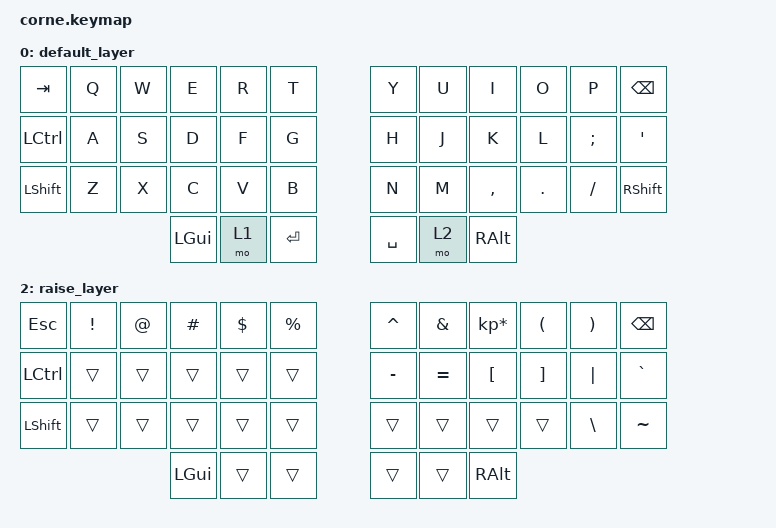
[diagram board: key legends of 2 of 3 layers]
/*
 * Copyright (c) 2020 The ZMK Contributors
 *
 * SPDX-License-Identifier: MIT
 */

#include <behaviors.dtsi>
#include <dt-bindings/zmk/keys.h>
#include <dt-bindings/zmk/bt.h>

/ {
        keymap {
                compatible = "zmk,keymap";

                default_layer {
// -----------------------------------------------------------------------------------------
// |  TAB |  Q  |  W  |  E  |  R  |  T  |   |  Y  |  U   |  I  |  O  |  P  | BKSP |
// | CTRL |  A  |  S  |  D  |  F  |  G  |   |  H  |  J   |  K  |  L  |  ;  |  '   |
// | SHFT |  Z  |  X  |  C  |  V  |  B  |   |  N  |  M   |  ,  |  .  |  /  | SHFT |
//                    | GUI | LWR | ENT |   | SPC | RSE  | ALT |
                        bindings = <
   &kp TAB   &kp Q &kp W &kp E    &kp R &kp T     &kp Y     &kp U &kp I     &kp O   &kp P    &kp BSPC
   &kp LCTRL &kp A &kp S &kp D    &kp F &kp G     &kp H     &kp J &kp K     &kp L   &kp SEMI &kp SQT
   &kp LSHFT &kp Z &kp X &kp C    &kp V &kp B     &kp N     &kp M &kp COMMA &kp DOT &kp FSLH &kp RSHFT
                         &kp LGUI &mo 1 &kp RET   &kp SPACE &mo 2 &kp RALT
                        >;
                };
                lower_layer {
// -----------------------------------------------------------------------------------------
// |  ESC |  1  |  2  |  3  |  4  |  5  |   |  6  |  7  |  8  |  9  |  0  | BKSP |
// | BTCLR| BT1 | BT2 | BT3 | BT4 | BT5 |   |     | LFT | DWN |  UP | RGT | RGBT |
// | SHFT | OTG | BLE | USB |     |     |   |     |     |     |     |     |      |
//                    | GUI |     | ENT |   | SPC |     | ALT |
                        bindings = <
   &kp ESC    &kp N1       &kp N2       &kp N3       &kp N4       &kp N5            &kp N6  &kp N7   &kp N8   &kp N9  &kp N0    &kp BSPC
   &bt BT_CLR &bt BT_SEL 0 &bt BT_SEL 1 &bt BT_SEL 2 &bt BT_SEL 3 &bt BT_SEL 4      &trans  &kp LEFT &kp DOWN &kp UP  &kp RIGHT &rgb_ug RGB_TOG
   &kp LSHFT  &out OUT_TOG &out OUT_BLE &out OUT_USB &trans       &trans            &trans  &trans   &trans   &trans  &trans
                                        &kp LGUI     &trans       &trans            &trans  &trans   &kp RALT
                        >;
                };

                raise_layer {
// -----------------------------------------------------------------------------------------
// |  ESC |  !  |  @  |  #  |  $  |  %  |   |  ^  |  &  |  *  |  (  |  )  | BKSP |
// | CTRL |     |     |     |     |     |   |  -  |  =  |  {  |  }  | "|" |  `   |
// | SHFT |     |     |     |     |     |   |  _  |  +  |  [  |  ]  |  \  |  ~   | // TODO: Fix this row when &mkp is committed
//                    | GUI |     | ENT |   | SPC |     | ALT |
                        bindings = <
   &kp  ESC  &kp EXCL  &kp AT  &kp HASH  &kp DLLR  &kp PRCNT   &kp CARET &kp AMPS  &kp KP_MULTIPLY &kp LPAR &kp RPAR &kp BSPC
   &kp LCTRL &trans    &trans  &trans    &trans    &trans      &kp MINUS &kp EQUAL &kp LBKT        &kp RBKT &kp PIPE &kp GRAVE
   &kp LSHFT &trans    &trans  &trans    &trans    &trans      &trans    &trans    &trans          &trans   &kp BSLH &kp TILDE
                               &kp LGUI  &trans    &trans      &trans    &trans    &kp RALT
                        >;
                };
        };
};
